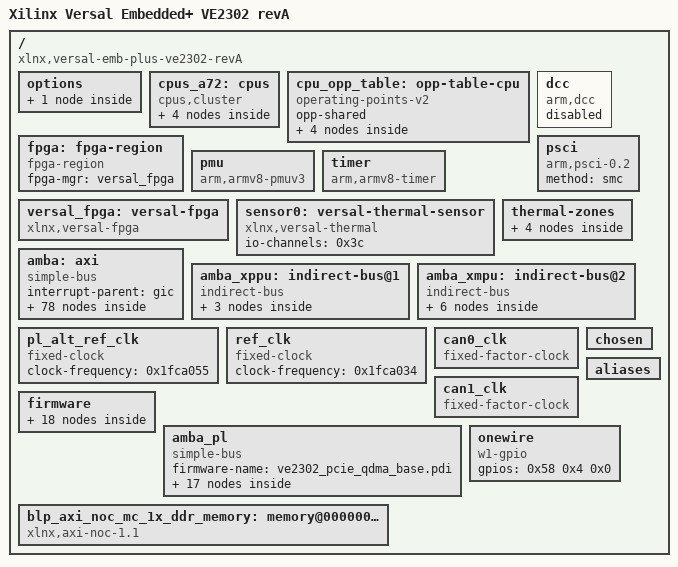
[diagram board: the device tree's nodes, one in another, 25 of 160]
/dts-v1/;

/ {
        compatible = "xlnx,versal-emb-plus-ve2302-revA", "xlnx,versal-emb-plus-ve2302", "xlnx,versal";
        #address-cells = <0x2>;
        #size-cells = <0x2>;
        model = "Xilinx Versal Embedded+ VE2302 revA";
        board = "emb-plus-vpr-4616";
        device_id = "xcve2302";
        slrcount = <0x1>;
        family = "Versal";

        options {

                u-boot {
                        compatible = "u-boot,config";
                        bootscr-address = <0x0 0x20000000>;
                };
        };

        cpus_a72: cpus {
                #address-cells = <0x1>;
                #size-cells = <0x0>;
                compatible = "cpus,cluster";
                #ranges-address-cells = <0x2>;
                #ranges-size-cells = <0x2>;
                phandle = <0xaf>;

                psv_cortexa72_0: cpu@0 {
                        compatible = "arm,cortex-a72", "arm,armv8";
                        device_type = "cpu";
                        enable-method = "psci";
                        operating-points-v2 = <&cpu_opp_table>;
                        reg = <0x0>;
                        cpu-idle-states = <&CPU_SLEEP_0>;
                        power-domains = <&versal_firmware 0x18110003>;
                        clocks = <&versal_clk 0x4d>;
                        xlnx,timestamp-clk-freq = <0x5f5e0a4>;
                        xlnx,pss-ref-clk-freq = <0x1fca034>;
                        stamp-frequency = <0x5f5e0a4>;
                        xlnx,ip-name = "psv_cortexa72";
                        xlnx,cpu-clk-freq-hz = <0x537248c1>;
                        cpu-frequency = <0x537248c1>;
                        bus-handle = <0x1>;
                        phandle = <0xb0>;
                };

                psv_cortexa72_1: cpu@1 {
                        compatible = "arm,cortex-a72", "arm,armv8";
                        device_type = "cpu";
                        enable-method = "psci";
                        operating-points-v2 = <&cpu_opp_table>;
                        reg = <0x1>;
                        cpu-idle-states = <&CPU_SLEEP_0>;
                        power-domains = <&versal_firmware 0x18110004>;
                        xlnx,timestamp-clk-freq = <0x5f5e0a4>;
                        xlnx,pss-ref-clk-freq = <0x1fca034>;
                        stamp-frequency = <0x5f5e0a4>;
                        xlnx,ip-name = "psv_cortexa72";
                        xlnx,cpu-clk-freq-hz = <0x537248c1>;
                        cpu-frequency = <0x537248c1>;
                        bus-handle = <0x1>;
                        phandle = <0xb1>;
                };

                idle-states {
                        entry-method = "psci";

                        CPU_SLEEP_0: cpu-sleep-0 {
                                compatible = "arm,idle-state";
                                arm,psci-suspend-param = <0x40000000>;
                                local-timer-stop;
                                entry-latency-us = <0x12c>;
                                exit-latency-us = <0x258>;
                                min-residency-us = <0x2710>;
                                phandle = <0x84>;
                        };
                };
        };

        cpu_opp_table: opp-table-cpu {
                compatible = "operating-points-v2";
                opp-shared;
                phandle = <0x83>;

                opp00 {
                        opp-hz = <0x0 0x47868bf4>;
                        opp-microvolt = <0xf4240>;
                        clock-latency-ns = <0x7a120>;
                };

                opp01 {
                        opp-hz = <0x0 0x23c345fa>;
                        opp-microvolt = <0xf4240>;
                        clock-latency-ns = <0x7a120>;
                };

                opp02 {
                        opp-hz = <0x0 0x17d783fc>;
                        opp-microvolt = <0xf4240>;
                        clock-latency-ns = <0x7a120>;
                };

                opp03 {
                        opp-hz = <0x0 0x11e1a2fd>;
                        opp-microvolt = <0xf4240>;
                        clock-latency-ns = <0x7a120>;
                };
        };

        dcc: dcc {
                compatible = "arm,dcc";
                status = "disabled";
                bootph-all;
                phandle = <0xba>;
        };

        fpga: fpga-region {
                compatible = "fpga-region";
                fpga-mgr = <&versal_fpga>;
                #address-cells = <0x2>;
                #size-cells = <0x2>;
                phandle = <0xbb>;
        };

        psci: psci {
                compatible = "arm,psci-0.2";
                method = "smc";
                phandle = <0xbc>;
        };

        pmu {
                compatible = "arm,armv8-pmuv3";
                interrupt-parent = <&gic>;
                interrupts = <0x1 0x7 0x304>;
        };

        timer: timer {
                compatible = "arm,armv8-timer";
                interrupt-parent = <&gic>;
                interrupts = <0x1 0xd 0x4 0x1 0xe 0x4 0x1 0xb 0x4 0x1 0xa 0x4>;
                phandle = <0xbd>;
        };

        versal_fpga: versal-fpga {
                compatible = "xlnx,versal-fpga";
                phandle = <0xa3>;
        };

        sensor0: versal-thermal-sensor {
                compatible = "xlnx,versal-thermal";
                #thermal-sensor-cells = <0x0>;
                io-channels = <0x3c>;
                io-channel-names = "sysmon-temp-channel";
                phandle = <0xa5>;
        };

        thermal-zones {

                versal_thermal: versal-thermal {
                        polling-delay-passive = <0xfa>;
                        polling-delay = <0x3e8>;
                        thermal-sensors = <0xa5>;
                        phandle = <0xbe>;

                        trips {

                                temp_alert: temp-alert {
                                        temperature = <0x11170>;
                                        hysteresis = <0x0>;
                                        type = "passive";
                                        phandle = <0xbf>;
                                };

                                ot_crit: ot-crit {
                                        temperature = <0x1e848>;
                                        hysteresis = <0x0>;
                                        type = "critical";
                                        phandle = <0xc0>;
                                };
                        };
                };
        };

        amba: axi {
                compatible = "simple-bus";
                #address-cells = <0x2>;
                #size-cells = <0x2>;
                ranges;
                interrupt-parent = <&gic>;
                bootph-all;
                phandle = <0x1>;

                can0: can@ff060000 {
                        compatible = "xlnx,canfd-2.0";
                        status = "disabled";
                        reg = <0x0 0xff060000 0x0 0x6000>;
                        interrupts = <0x0 0x14 0x4>;
                        interrupt-parent = <&gic>;
                        clock-names = "can_clk", "s_axi_aclk";
                        rx-fifo-depth = <0x40>;
                        tx-mailbox-count = <0x20>;
                        clocks = <&can0_clk>,
                         <&versal_clk 0x52>;
                        power-domains = <&versal_firmware 0x1822401f>;
                        phandle = <0xc1>;
                };

                can1: can@ff070000 {
                        compatible = "xlnx,canfd-2.0";
                        status = "disabled";
                        reg = <0x0 0xff070000 0x0 0x6000>;
                        interrupts = <0x0 0x15 0x4>;
                        interrupt-parent = <&gic>;
                        clock-names = "can_clk", "s_axi_aclk";
                        rx-fifo-depth = <0x40>;
                        tx-mailbox-count = <0x20>;
                        clocks = <&can1_clk>,
                         <&versal_clk 0x52>;
                        power-domains = <&versal_firmware 0x18224020>;
                        phandle = <0xc2>;
                };

                cci: cci@fd000000 {
                        compatible = "arm,cci-500";
                        status = "okay";
                        reg = <0x0 0xfd000000 0x0 0x10000>;
                        ranges = <0x0 0x0 0xfd000000 0xa0000>;
                        #address-cells = <0x1>;
                        #size-cells = <0x1>;
                        xlnx,ip-name = "psv_fpd_maincci";
                        phandle = <0x47>;

                        cci_pmu: pmu@10000 {
                                compatible = "arm,cci-500-pmu,r0";
                                reg = <0x10000 0x90000>;
                                interrupt-parent = <&gic>;
                                interrupts = <0x0 0x6a 0x4 0x0 0x6a 0x4 0x0 0x6a 0x4 0x0 0x6a 0x4 0x0 0x6a 0x4 0x0 0x6a 0x4 0x0 0x6a 0x4 0x0 0x6a 0x4>;
                                phandle = <0xc3>;
                        };
                };

                lpd_dma_chan0: dma-controller@ffa80000 {
                        compatible = "xlnx,zynqmp-dma-1.0";
                        status = "okay";
                        reg = <0x0 0xffa80000 0x0 0x1000>;
                        interrupts = <0x0 0x3c 0x4>;
                        interrupt-parent = <&gic>;
                        clock-names = "clk_main", "clk_apb";
                        xlnx,dma-type = <0x1>;
                        #dma-cells = <0x1>;
                        xlnx,bus-width = <0x40>;
                        clocks = <&versal_clk 0x51>,
                         <&versal_clk 0x52>;
                        power-domains = <&versal_firmware 0x18224035>;
                        xlnx,is-cache-coherent = <0x0>;
                        xlnx,ip-name = "psv_adma";
                        xlnx,dma-mode = <0x1>;
                        phandle = <0x72>;
                };

                lpd_dma_chan1: dma-controller@ffa90000 {
                        compatible = "xlnx,zynqmp-dma-1.0";
                        status = "okay";
                        reg = <0x0 0xffa90000 0x0 0x1000>;
                        interrupts = <0x0 0x3d 0x4>;
                        interrupt-parent = <&gic>;
                        clock-names = "clk_main", "clk_apb";
                        xlnx,dma-type = <0x1>;
                        #dma-cells = <0x1>;
                        xlnx,bus-width = <0x40>;
                        clocks = <&versal_clk 0x51>,
                         <&versal_clk 0x52>;
                        power-domains = <&versal_firmware 0x18224036>;
                        xlnx,is-cache-coherent = <0x0>;
                        xlnx,ip-name = "psv_adma";
                        xlnx,dma-mode = <0x1>;
                        phandle = <0x73>;
                };

                lpd_dma_chan2: dma-controller@ffaa0000 {
                        compatible = "xlnx,zynqmp-dma-1.0";
                        status = "okay";
                        reg = <0x0 0xffaa0000 0x0 0x1000>;
                        interrupts = <0x0 0x3e 0x4>;
                        interrupt-parent = <&gic>;
                        clock-names = "clk_main", "clk_apb";
                        xlnx,dma-type = <0x1>;
                        #dma-cells = <0x1>;
                        xlnx,bus-width = <0x40>;
                        clocks = <&versal_clk 0x51>,
                         <&versal_clk 0x52>;
                        power-domains = <&versal_firmware 0x18224037>;
                        xlnx,is-cache-coherent = <0x0>;
                        xlnx,ip-name = "psv_adma";
                        xlnx,dma-mode = <0x1>;
                        phandle = <0x74>;
                };

                lpd_dma_chan3: dma-controller@ffab0000 {
                        compatible = "xlnx,zynqmp-dma-1.0";
                        status = "okay";
                        reg = <0x0 0xffab0000 0x0 0x1000>;
                        interrupts = <0x0 0x3f 0x4>;
                        interrupt-parent = <&gic>;
                        clock-names = "clk_main", "clk_apb";
                        xlnx,dma-type = <0x1>;
                        #dma-cells = <0x1>;
                        xlnx,bus-width = <0x40>;
                        clocks = <&versal_clk 0x51>,
                         <&versal_clk 0x52>;
                        power-domains = <&versal_firmware 0x18224038>;
                        xlnx,is-cache-coherent = <0x0>;
                        xlnx,ip-name = "psv_adma";
                        xlnx,dma-mode = <0x1>;
                        phandle = <0x75>;
                };

                lpd_dma_chan4: dma-controller@ffac0000 {
                        compatible = "xlnx,zynqmp-dma-1.0";
                        status = "okay";
                        reg = <0x0 0xffac0000 0x0 0x1000>;
                        interrupts = <0x0 0x40 0x4>;
                        interrupt-parent = <&gic>;
                        clock-names = "clk_main", "clk_apb";
                        xlnx,dma-type = <0x1>;
                        #dma-cells = <0x1>;
                        xlnx,bus-width = <0x40>;
                        clocks = <&versal_clk 0x51>,
                         <&versal_clk 0x52>;
                        power-domains = <&versal_firmware 0x18224039>;
                        xlnx,is-cache-coherent = <0x0>;
                        xlnx,ip-name = "psv_adma";
                        xlnx,dma-mode = <0x1>;
                        phandle = <0x76>;
                };

                lpd_dma_chan5: dma-controller@ffad0000 {
                        compatible = "xlnx,zynqmp-dma-1.0";
                        status = "okay";
                        reg = <0x0 0xffad0000 0x0 0x1000>;
                        interrupts = <0x0 0x41 0x4>;
                        interrupt-parent = <&gic>;
                        clock-names = "clk_main", "clk_apb";
                        xlnx,dma-type = <0x1>;
                        #dma-cells = <0x1>;
                        xlnx,bus-width = <0x40>;
                        clocks = <&versal_clk 0x51>,
                         <&versal_clk 0x52>;
                        power-domains = <&versal_firmware 0x1822403a>;
                        xlnx,is-cache-coherent = <0x0>;
                        xlnx,ip-name = "psv_adma";
                        xlnx,dma-mode = <0x1>;
                        phandle = <0x77>;
                };

                lpd_dma_chan6: dma-controller@ffae0000 {
                        compatible = "xlnx,zynqmp-dma-1.0";
                        status = "okay";
                        reg = <0x0 0xffae0000 0x0 0x1000>;
                        interrupts = <0x0 0x42 0x4>;
                        interrupt-parent = <&gic>;
                        clock-names = "clk_main", "clk_apb";
                        xlnx,dma-type = <0x1>;
                        #dma-cells = <0x1>;
                        xlnx,bus-width = <0x40>;
                        clocks = <&versal_clk 0x51>,
                         <&versal_clk 0x52>;
                        power-domains = <&versal_firmware 0x1822403b>;
                        xlnx,is-cache-coherent = <0x0>;
                        xlnx,ip-name = "psv_adma";
                        xlnx,dma-mode = <0x1>;
                        phandle = <0x78>;
                };

                lpd_dma_chan7: dma-controller@ffaf0000 {
                        compatible = "xlnx,zynqmp-dma-1.0";
                        status = "okay";
                        reg = <0x0 0xffaf0000 0x0 0x1000>;
                        interrupts = <0x0 0x43 0x4>;
                        interrupt-parent = <&gic>;
                        clock-names = "clk_main", "clk_apb";
                        xlnx,dma-type = <0x1>;
                        #dma-cells = <0x1>;
                        xlnx,bus-width = <0x40>;
                        clocks = <&versal_clk 0x51>,
                         <&versal_clk 0x52>;
                        power-domains = <&versal_firmware 0x1822403c>;
                        xlnx,is-cache-coherent = <0x0>;
                        xlnx,ip-name = "psv_adma";
                        xlnx,dma-mode = <0x1>;
                        phandle = <0x79>;
                };

                gem0: ethernet@ff0c0000 {
                        compatible = "xlnx,versal-gem", "cdns,gem";
                        status = "disabled";
                        reg = <0x0 0xff0c0000 0x0 0x1000>;
                        interrupts = <0x0 0x38 0x4 0x0 0x38 0x4>;
                        interrupt-parent = <&gic>;
                        clock-names = "pclk", "hclk", "tx_clk", "rx_clk", "tsu_clk";
                        #address-cells = <0x1>;
                        #size-cells = <0x0>;
                        clocks = <&versal_clk 0x52>,
                         <&versal_clk 0x58>,
                         <&versal_clk 0x31>,
                         <&versal_clk 0x30>,
                         <&versal_clk 0x2b>;
                        power-domains = <&versal_firmware 0x18224019>;
                        phandle = <0xc4>;
                };

                gem1: ethernet@ff0d0000 {
                        compatible = "xlnx,versal-gem", "cdns,gem";
                        status = "disabled";
                        reg = <0x0 0xff0d0000 0x0 0x1000>;
                        interrupts = <0x0 0x3a 0x4 0x0 0x3a 0x4>;
                        interrupt-parent = <&gic>;
                        clock-names = "pclk", "hclk", "tx_clk", "rx_clk", "tsu_clk";
                        #address-cells = <0x1>;
                        #size-cells = <0x0>;
                        clocks = <&versal_clk 0x52>,
                         <&versal_clk 0x59>,
                         <&versal_clk 0x33>,
                         <&versal_clk 0x32>,
                         <&versal_clk 0x2b>;
                        power-domains = <&versal_firmware 0x1822401a>;
                        phandle = <0xc5>;
                };

                gpio0: gpio@ff0b0000 {
                        compatible = "xlnx,versal-gpio-1.0";
                        status = "okay";
                        reg = <0x0 0xff0b0000 0x0 0x1000>;
                        interrupts = <0x0 0xd 0x4>;
                        interrupt-parent = <&gic>;
                        #gpio-cells = <0x2>;
                        gpio-controller;
                        #interrupt-cells = <0x2>;
                        interrupt-controller;
                        clocks = <&versal_clk 0x52>;
                        power-domains = <&versal_firmware 0x18224023>;
                        xlnx,ip-name = "psv_gpio";
                        emio-gpio-width = [00];
                        gpio-line-names = [47 50 49 4F 5F 4C 45 44 32 00 47 50 49 4F 5F 4C 45 44 33 00 47 50 49 4F 5F 4C 45 44 34 00 00 31 57 49 52 45 00 00 46 55 53 41 00 00 45 47 50 49 4F 00 41 47 50 49 4F 00 49 32 43 30 5F 53 43 4C 00 49 32 43 30 5F 53 44 41 00 00 00 00 00 00 00 00 00 00 00 00 00 33 56 33 5F 4D 4F 4E 5F 4E 00 33 56 33 5F 4D 4F 4E 5F 50 00 00 00 00 00 00 00 00 00 00 00 00 00 00 00 00 00 00 00 00 00 00 00 00 00 00 00 00 00 00 00 00];
                        phandle = <0x58>;
                };

                gpio1: gpio@f1020000 {
                        compatible = "xlnx,pmc-gpio-1.0";
                        status = "okay";
                        reg = <0x0 0xf1020000 0x0 0x1000>;
                        interrupts = <0x0 0x7a 0x4>;
                        interrupt-parent = <&gic>;
                        #gpio-cells = <0x2>;
                        gpio-controller;
                        #interrupt-cells = <0x2>;
                        interrupt-controller;
                        clocks = <&versal_clk 0x3d>;
                        power-domains = <&versal_firmware 0x1822402c>;
                        xlnx,ip-name = "psv_pmc_gpio";
                        phandle = <0x2f>;
                };

                i2c0: i2c@ff020000 {
                        compatible = "cdns,i2c-r1p14";
                        status = "disabled";
                        reg = <0x0 0xff020000 0x0 0x1000>;
                        interrupts = <0x0 0xe 0x4>;
                        interrupt-parent = <&gic>;
                        clock-frequency = <0x186a0>;
                        #address-cells = <0x1>;
                        #size-cells = <0x0>;
                        clocks = <&versal_clk 0x62>;
                        power-domains = <&versal_firmware 0x1822401d>;
                        phandle = <0xc6>;
                };

                i2c1: i2c@ff030000 {
                        compatible = "cdns,i2c-r1p14";
                        status = "disabled";
                        reg = <0x0 0xff030000 0x0 0x1000>;
                        interrupts = <0x0 0xf 0x4>;
                        interrupt-parent = <&gic>;
                        clock-frequency = <0x186a0>;
                        #address-cells = <0x1>;
                        #size-cells = <0x0>;
                        clocks = <&versal_clk 0x63>;
                        power-domains = <&versal_firmware 0x1822401e>;
                        phandle = <0xc7>;
                };

                i2c2: i2c@f1000000 {
                        compatible = "cdns,i2c-r1p14";
                        status = "okay";
                        reg = <0x0 0xf1000000 0x0 0x1000>;
                        interrupts = <0x0 0x7b 0x4>;
                        interrupt-parent = <&gic>;
                        clock-frequency = <0x186a0>;
                        #address-cells = <0x1>;
                        #size-cells = <0x0>;
                        clocks = <&versal_clk 0x3e>;
                        power-domains = <&versal_firmware 0x1822402d>;
                        xlnx,clock-freq = <0x5f5e0a4>;
                        xlnx,i2c-clk-freq-hz = <0x5f5e0a4>;
                        xlnx,ip-name = "psv_pmc_i2c";
                        phandle = <0x2d>;
                };

                mc1: memory-controller@f62c0000 {
                        compatible = "xlnx,versal-ddrmc";
                        status = "disabled";
                        reg = <0x0 0xf62c0000 0x0 0x2000 0x0 0xf6210000 0x0 0x20000>;
                        reg-names = "base", "noc";
                        interrupts = <0x0 0x93 0x4>;
                        interrupt-parent = <&gic>;
                        phandle = <0xc9>;
                };

                mc2: memory-controller@f6430000 {
                        compatible = "xlnx,versal-ddrmc";
                        status = "disabled";
                        reg = <0x0 0xf6430000 0x0 0x2000 0x0 0xf6380000 0x0 0x20000>;
                        reg-names = "base", "noc";
                        interrupts = <0x0 0x93 0x4>;
                        interrupt-parent = <&gic>;
                        phandle = <0xca>;
                };

                mc3: memory-controller@f65a0000 {
                        compatible = "xlnx,versal-ddrmc";
                        status = "disabled";
                        reg = <0x0 0xf65a0000 0x0 0x2000 0x0 0xf64f0000 0x0 0x20000>;
                        reg-names = "base", "noc";
                        interrupts = <0x0 0x93 0x4>;
                        interrupt-parent = <&gic>;
                        phandle = <0xcb>;
                };

                ocm: memory-controller@ff960000 {
                        compatible = "xlnx,zynqmp-ocmc-1.0";
                        reg = <0x0 0xff960000 0x0 0x1000>;
                        interrupts = <0x0 0xa 0x4>;
                        interrupt-parent = <&gic>;
                        phandle = <0xcc>;
                };

                rtc: rtc@f12a0000 {
                        compatible = "xlnx,zynqmp-rtc";
                        status = "okay";
                        reg = <0x0 0xf12a0000 0x0 0x100>;
                        interrupt-names = "alarm", "sec";
                        interrupts = <0x0 0x8e 0x4 0x0 0x8f 0x4>;
                        interrupt-parent = <&gic>;
                        calibration = <0x7fff>;
                        power-domains = <&versal_firmware 0x18224034>;
                        xlnx,ip-name = "psv_pmc_rtc";
                        phandle = <0x3d>;
                };

                sdhci0: mmc@f1040000 {
                        compatible = "xlnx,versal-8.9a", "arasan,sdhci-8.9a";
                        status = "disabled";
                        reg = <0x0 0xf1040000 0x0 0x10000>;
                        interrupts = <0x0 0x7e 0x4>;
                        interrupt-parent = <&gic>;
                        clock-names = "clk_xin", "clk_ahb", "gate";
                        #clock-cells = <0x1>;
                        clock-output-names = "clk_out_sd0", "clk_in_sd0";
                        clocks = <&versal_clk 0x3b>,
                         <&versal_clk 0x52>,
                         <&versal_clk 0x4a>;
                        power-domains = <&versal_firmware 0x1822402e>;
                        phandle = <0xcd>;
                };

                sdhci1: mmc@f1050000 {
                        compatible = "xlnx,versal-8.9a", "arasan,sdhci-8.9a";
                        status = "disabled";
                        reg = <0x0 0xf1050000 0x0 0x10000>;
                        interrupts = <0x0 0x80 0x4>;
                        interrupt-parent = <&gic>;
                        clock-names = "clk_xin", "clk_ahb", "gate";
                        #clock-cells = <0x1>;
                        clock-output-names = "clk_out_sd1", "clk_in_sd1";
                        clocks = <&versal_clk 0x3c>,
                         <&versal_clk 0x52>,
                         <&versal_clk 0x4a>;
                        power-domains = <&versal_firmware 0x1822402f>;
                        phandle = <0xce>;
                };

                serial0: serial@ff000000 {
                        compatible = "arm,pl011", "arm,primecell";
                        status = "okay";
                        reg = <0x0 0xff000000 0x0 0x1000>;
                        interrupts = <0x0 0x12 0x4>;
                        interrupt-parent = <&gic>;
                        reg-io-width = <0x4>;
                        clock-names = "uartclk", "apb_pclk";
                        bootph-all;
                        clocks = <&versal_clk 0x5c>,
                         <&versal_clk 0x52>;
                        power-domains = <&versal_firmware 0x18224021>;
                        xlnx,has-modem = <0x0>;
                        xlnx,uart-clk-freq-hz = <0x5f5e0a4>;
                        port-number = <0x0>;
                        xlnx,ip-name = "psv_sbsauart";
                        xlnx,uart-board-interface = "custom";
                        xlnx,baudrate = <0x1c200>;
                        cts-override;
                        u-boot,dm-pre-reloc;
                        xlnx,clock-freq = <0x5f5e0a4>;
                        phandle = <0x53>;
                };

                serial1: serial@ff010000 {
                        compatible = "arm,pl011", "arm,primecell";
                        status = "okay";
                        reg = <0x0 0xff010000 0x0 0x1000>;
                        interrupts = <0x0 0x13 0x4>;
                        interrupt-parent = <&gic>;
                        reg-io-width = <0x4>;
                        clock-names = "uartclk", "apb_pclk";
                        bootph-all;
                        clocks = <&versal_clk 0x5d>,
                         <&versal_clk 0x52>;
                        power-domains = <&versal_firmware 0x18224022>;
                        xlnx,has-modem = <0x0>;
                        xlnx,uart-clk-freq-hz = <0x5f5e0a4>;
                        port-number = <0x0>;
                        xlnx,ip-name = "psv_sbsauart";
                        xlnx,uart-board-interface = "custom";
                        xlnx,baudrate = <0x1c200>;
                        cts-override;
                        u-boot,dm-pre-reloc;
                        xlnx,clock-freq = <0x5f5e0a4>;
                        phandle = <0x54>;
                };

                smmu: iommu@fd800000 {
                        compatible = "arm,mmu-500";
                        status = "okay";
                        reg = <0x0 0xfd800000 0x0 0x40000>;
                        stream-match-mask = <0x7c00>;
                        #iommu-cells = <0x1>;
                        #global-interrupts = <0x1>;
                        interrupts = <0x0 0x6b 0x4 0x0 0x6b 0x4 0x0 0x6b 0x4 0x0 0x6b 0x4 0x0 0x6b 0x4 0x0 0x6b 0x4 0x0 0x6b 0x4 0x0 0x6b 0x4 0x0 0x6b 0x4 0x0 0x6b 0x4 0x0 0x6b 0x4 0x0 0x6b 0x4 0x0 0x6b 0x4 0x0 0x6b 0x4 0x0 0x6b 0x4 0x0 0x6b 0x4 0x0 0x6b 0x4 0x0 0x6b 0x4 0x0 0x6b 0x4 0x0 0x6b 0x4 0x0 0x6b 0x4 0x0 0x6b 0x4 0x0 0x6b 0x4 0x0 0x6b 0x4 0x0 0x6b 0x4 0x0 0x6b 0x4 0x0 0x6b 0x4 0x0 0x6b 0x4 0x0 0x6b 0x4 0x0 0x6b 0x4 0x0 0x6b 0x4 0x0 0x6b 0x4 0x0 0x6b 0x4>;
                        interrupt-parent = <&gic>;
                        xlnx,ip-name = "psv_fpd_smmutcu";
                        phandle = <0x52>;
                };

                ospi: spi@f1010000 {
                        compatible = "xlnx,versal-ospi-1.0", "cdns,qspi-nor";
                        status = "okay";
                        reg = <0x0 0xf1010000 0x0 0x10000 0x0 0xc0000000 0x0 0x20000000>;
                        interrupts = <0x0 0x7c 0x4>;
                        interrupt-parent = <&gic>;
                        cdns,fifo-depth = <0x100>;
                        cdns,fifo-width = <0x4>;
                        cdns,is-dma = <0x1>;
                        cdns,trigger-address = <0xc0000000>;
                        #address-cells = <0x1>;
                        #size-cells = <0x0>;
                        clocks = <&versal_clk 0x3a>;
                        power-domains = <&versal_firmware 0x1822402a>;
                        reset-names = "qspi";
                        resets = <&versal_reset 0xc10402e>;
                        is-stacked = <0x0>;
                        xlnx,is-cache-coherent = <0x0>;
                        xlnx,clock-freq = <0xbebc149>;
                        xlnx,ip-name = "psv_pmc_ospi";
                        xlnx,ospi-clk-freq-hz = <0xbebc149>;
                        is-dual = <0x0>;
                        xlnx,ospi-mode = <0x0>;
                        phandle = <0x2e>;
                };

                qspi: spi@f1030000 {
                        compatible = "xlnx,versal-qspi-1.0";
                        status = "disabled";
                        reg = <0x0 0xf1030000 0x0 0x1000>;
                        interrupts = <0x0 0x7d 0x4>;
                        interrupt-parent = <&gic>;
                        clock-names = "ref_clk", "pclk";
                        #address-cells = <0x1>;
                        #size-cells = <0x0>;
                        clocks = <&versal_clk 0x39>,
                         <&versal_clk 0x52>;
                        power-domains = <&versal_firmware 0x1822402b>;
                        phandle = <0xcf>;
                };

                spi0: spi@ff040000 {
                        compatible = "cdns,spi-r1p6";
                        status = "okay";
                        reg = <0x0 0xff040000 0x0 0x1000>;
                        interrupts = <0x0 0x10 0x4>;
                        interrupt-parent = <&gic>;
                        clock-names = "ref_clk", "pclk";
                        #address-cells = <0x1>;
                        #size-cells = <0x0>;
                        clocks = <&versal_clk 0x5e>,
                         <&versal_clk 0x52>;
                        power-domains = <&versal_firmware 0x1822401b>;
                        xlnx,spi-board-interface = "custom";
                        xlnx,has-ss0 = <0x1>;
                        xlnx,ip-name = "psv_spi";
                        xlnx,has-ss1 = <0x0>;
                        num-cs = <0x1>;
                        xlnx,spi-clk-freq-hz = <0xbebc149>;
                        xlnx,has-ss2 = <0x0>;
                        phandle = <0x55>;
                };

                spi1: spi@ff050000 {
                        compatible = "cdns,spi-r1p6";
                        status = "disabled";
                        reg = <0x0 0xff050000 0x0 0x1000>;
                        interrupts = <0x0 0x11 0x4>;
                        interrupt-parent = <&gic>;
                        clock-names = "ref_clk", "pclk";
                        #address-cells = <0x1>;
                        #size-cells = <0x0>;
                        clocks = <&versal_clk 0x5f>,
                         <&versal_clk 0x52>;
                        power-domains = <&versal_firmware 0x1822401c>;
                        phandle = <0xd0>;
                };

                sysmon0: sysmon@f1270000 {
                        compatible = "xlnx,versal-sysmon";
                        #io-channel-cells = <0x0>;
                        reg = <0x0 0xf1270000 0x0 0x4000>;
                        interrupts = <0x0 0x90 0x4>;
                        xlnx,numchannels = [0B];
                        #address-cells = <0x2>;
                        #size-cells = <0x2>;
                        xlnx,nodeid = <0x18224055>;
                        xlnx,sat-63-desc = "PS , FPD , satellite";
                        xlnx,sat-1-desc = "PMC , system , ADC";
                        xlnx,sat-9-x = <0xae2>;
                        xlnx,sat-9-y = <0x2905>;
                        xlnx,meas-0-root-id = <0x1>;
                        xlnx,meas-7-slr-number = <0x0>;
                        xlnx,meas-10-root-id = <0x0>;
                        xlnx,ip-name = "psv_pmc_sysmon";
                        xlnx,meas-1-root-id = <0x5>;
                        xlnx,meas-2-root-id = <0x8>;
                        xlnx,meas-2-slr-number = <0x0>;
                        xlnx,meas-3-root-id = <0xa>;
                        xlnx,sat-9-desc = "ME , satellite";
                        xlnx,meas-4-root-id = <0x7>;
                        xlnx,meas-5-root-id = <0x2>;
                        xlnx,sat-10-x = <0x319>;
                        xlnx,sat-64-x = <0x23>;
                        xlnx,sat-2-x = <0x23>;
                        xlnx,meas-6-root-id = <0x3>;
                        xlnx,sat-10-y = <0x2905>;
                        xlnx,sat-64-y = <0xb34>;
                        xlnx,sat-2-y = <0xb34>;
                        xlnx,sat-13-desc = "Clocking , column , satellite";
                        xlnx,meas-7-root-id = <0x4>;
                        xlnx,meas-8-root-id = <0x6>;
                        xlnx,sat-6-desc = "VNOC , satellite";
                        xlnx,meas-9-root-id = <0x9>;
                        xlnx,sat-6-x = <0x1a37>;
                        xlnx,sat-6-y = <0x19f9>;
                        xlnx,sat-10-desc = "ME , satellite";
                        xlnx,sat-3-desc = "XPIO , satellite";
                        xlnx,meas-5-slr-number = <0x0>;
                        xlnx,meas-10-aux-io-n = "LPD_MIO25_502";
                        xlnx,meas-0-slr-number = <0x0>;
                        xlnx,meas-10-aux-io-p = "LPD_MIO24_502";
                        xlnx,sat-11-x = <0xa0e>;
                        xlnx,sat-3-x = <0x116a>;
                        xlnx,sat-11-y = <0x23fc>;
                        xlnx,sat-3-y = <0x5ff>;
                        status = "okay";
                        xlnx,meas-8-slr-number = <0x0>;
                        xlnx,sat-8-desc = "ME , satellite";
                        xlnx,sat-7-x = <0x1a74>;
                        xlnx,sat-7-y = <0x2905>;
                        xlnx,meas-3-slr-number = <0x0>;
                        xlnx,sat-12-desc = "Clocking , column , satellite";
                        xlnx,sat-5-desc = "VNOC , satellite";
                        xlnx,sat-64-desc = "PS , LPD , satellite";
                        xlnx,sat-2-desc = "PMC , user , ADC";
                        xlnx,meas-6-slr-number = <0x0>;
                        xlnx,sat-12-x = <0xa0e>;
                        xlnx,sat-4-x = <0x1d4c>;
                        xlnx,sat-12-y = <0x1dc4>;
                        xlnx,sat-4-y = <0x5ff>;
                        xlnx,meas-10-slr-number = <0x0>;
                        xlnx,meas-1-slr-number = <0x0>;
                        xlnx,sat-8-x = <0x12ab>;
                        xlnx,sat-8-y = <0x2905>;
                        xlnx,meas-0 = "VCCAUX";
                        xlnx,meas-10 = "VAUX_CH0";
                        xlnx,meas-1 = "VCC_SOC";
                        xlnx,meas-2 = "VCCO_302";
                        xlnx,meas-3 = "VCCAUX_PMC";
                        xlnx,meas-4 = "VCCO_500";
                        xlnx,sat-7-desc = "ME , satellite";
                        xlnx,meas-5 = "VCC_PMC";
                        xlnx,meas-9-slr-number = <0x0>;
                        xlnx,meas-6 = "VCC_PSFP";
                        xlnx,meas-7 = "VCC_PSLP";
                        xlnx,sat-63-x = <0x23>;
                        xlnx,sat-1-x = <0x23>;
                        xlnx,meas-4-slr-number = <0x0>;
                        xlnx,meas-8 = "VP_VN";
                        xlnx,sat-11-desc = "Clocking , column , satellite";
                        xlnx,sat-63-y = <0xb34>;
                        xlnx,sat-1-y = <0xb34>;
                        xlnx,meas-9 = "VCCO_703";
                        xlnx,sat-4-desc = "XPIO , satellite";
                        xlnx,sat-13-x = <0xa0e>;
                        xlnx,sat-5-x = <0x1a37>;
                        xlnx,sat-13-y = <0x1795>;
                        xlnx,sat-5-y = <0xe06>;
                        phandle = <0x3c>;

                        supply@1 {
                                reg = <0x1>;
                                xlnx,name = "vccaux";
                        };

                        supply@5 {
                                reg = <0x5>;
                                xlnx,name = "vcc_soc";
                        };

                        supply@8 {
                                reg = <0x8>;
                                xlnx,name = "vcco_302";
                        };

                        supply@10 {
                                reg = <0xa>;
                                xlnx,name = "vccaux_pmc";
                        };

                        supply@7 {
                                reg = <0x7>;
                                xlnx,name = "vcco_500";
                        };

                        supply@2 {
                                reg = <0x2>;
                                xlnx,name = "vcc_pmc";
                        };

                        supply@3 {
                                reg = <0x3>;
                                xlnx,name = "vcc_psfp";
                        };

                        supply@4 {
                                reg = <0x4>;
                                xlnx,name = "vcc_pslp";
                        };

                        supply@6 {
                                reg = <0x6>;
                                xlnx,name = "vp_vn";
                        };

                        supply@9 {
                                reg = <0x9>;
                                xlnx,name = "vcco_703";
                        };

                        supply@0 {
                                reg = <0x0>;
                                xlnx,name = "vaux_ch0";
                        };
                };

                sysmon1: sysmon@109270000 {
                        compatible = "xlnx,versal-sysmon";
                        status = "disabled";
                        reg = <0x1 0x9270000 0x0 0x4000>;
                        xlnx,numchannels = [00];
                        #address-cells = <0x1>;
                        #size-cells = <0x0>;
                        xlnx,nodeid = <0x18225055>;
                        phandle = <0xd1>;
                };

                sysmon2: sysmon@111270000 {
                        compatible = "xlnx,versal-sysmon";
                        status = "disabled";
                        reg = <0x1 0x11270000 0x0 0x4000>;
                        xlnx,numchannels = [00];
                        #address-cells = <0x1>;
                        #size-cells = <0x0>;
                        xlnx,nodeid = <0x18226055>;
                        phandle = <0xd2>;
                };

                sysmon3: sysmon@119270000 {
                        compatible = "xlnx,versal-sysmon";
                        status = "disabled";
                        reg = <0x1 0x19270000 0x0 0x4000>;
                        xlnx,numchannels = [00];
                        #address-cells = <0x1>;
                        #size-cells = <0x0>;
                        xlnx,nodeid = <0x18227055>;
                        phandle = <0xd3>;
                };

                ttc0: timer@ff0e0000 {
                        compatible = "cdns,ttc";
                        status = "okay";
                        interrupts = <0x0 0x25 0x4 0x0 0x26 0x4 0x0 0x27 0x4>;
                        interrupt-parent = <&gic>;
                        reg = <0x0 0xff0e0000 0x0 0x1000>;
                        timer-width = <0x20>;
                        clocks = <&versal_clk 0x27>,
                         <&versal_clk 0x52>;
                        power-domains = <&versal_firmware 0x18224024>;
                        xlnx,ttc-clk2-clksrc = <0x0>;
                        xlnx,ip-name = "psv_ttc";
                        xlnx,ttc-clk1-clksrc = <0x0>;
                        xlnx,ttc-clk0-freq-hz = <0x8f0d0f7>;
                        xlnx,ttc-clk1-freq-hz = <0x8f0d0f7>;
                        xlnx,ttc-clk2-freq-hz = <0x8f0d0f7>;
                        xlnx,ttc-board-interface = "custom";
                        xlnx,clock-freq = <0x8f0d0f7>;
                        xlnx,ttc-clk0-clksrc = <0x0>;
                        phandle = <0x59>;
                };

                ttc1: timer@ff0f0000 {
                        compatible = "cdns,ttc";
                        status = "okay";
                        interrupts = <0x0 0x28 0x4 0x0 0x29 0x4 0x0 0x2a 0x4>;
                        interrupt-parent = <&gic>;
                        reg = <0x0 0xff0f0000 0x0 0x1000>;
                        timer-width = <0x20>;
                        clocks = <&versal_clk 0x28>,
                         <&versal_clk 0x52>;
                        power-domains = <&versal_firmware 0x18224025>;
                        xlnx,ttc-clk2-clksrc = <0x0>;
                        xlnx,ip-name = "psv_ttc";
                        xlnx,ttc-clk1-clksrc = <0x0>;
                        xlnx,ttc-clk0-freq-hz = <0x8f0d0f7>;
                        xlnx,ttc-clk1-freq-hz = <0x8f0d0f7>;
                        xlnx,ttc-clk2-freq-hz = <0x8f0d0f7>;
                        xlnx,ttc-board-interface = "custom";
                        xlnx,clock-freq = <0x8f0d0f7>;
                        xlnx,ttc-clk0-clksrc = <0x0>;
                        phandle = <0x5a>;
                };

                ttc2: timer@ff100000 {
                        compatible = "cdns,ttc";
                        status = "okay";
                        interrupts = <0x0 0x2b 0x4 0x0 0x2c 0x4 0x0 0x2d 0x4>;
                        interrupt-parent = <&gic>;
                        reg = <0x0 0xff100000 0x0 0x1000>;
                        timer-width = <0x20>;
                        clocks = <&versal_clk 0x29>,
                         <&versal_clk 0x52>;
                        power-domains = <&versal_firmware 0x18224026>;
                        xlnx,ttc-clk2-clksrc = <0x0>;
                        xlnx,ip-name = "psv_ttc";
                        xlnx,ttc-clk1-clksrc = <0x0>;
                        xlnx,ttc-clk0-freq-hz = <0x8f0d0f7>;
                        xlnx,ttc-clk1-freq-hz = <0x8f0d0f7>;
                        xlnx,ttc-clk2-freq-hz = <0x8f0d0f7>;
                        xlnx,ttc-board-interface = "custom";
                        xlnx,clock-freq = <0x8f0d0f7>;
                        xlnx,ttc-clk0-clksrc = <0x0>;
                        phandle = <0x5b>;
                };

                ttc3: timer@ff110000 {
                        compatible = "cdns,ttc";
                        status = "okay";
                        interrupts = <0x0 0x2e 0x4 0x0 0x2f 0x4 0x0 0x30 0x4>;
                        interrupt-parent = <&gic>;
                        reg = <0x0 0xff110000 0x0 0x1000>;
                        timer-width = <0x20>;
                        clocks = <&versal_clk 0x2a>,
                         <&versal_clk 0x52>;
                        power-domains = <&versal_firmware 0x18224027>;
                        xlnx,ttc-clk2-clksrc = <0x0>;
                        xlnx,ip-name = "psv_ttc";
                        xlnx,ttc-clk1-clksrc = <0x0>;
                        xlnx,ttc-clk0-freq-hz = <0x8f0d0f7>;
                        xlnx,ttc-clk1-freq-hz = <0x8f0d0f7>;
                        xlnx,ttc-clk2-freq-hz = <0x8f0d0f7>;
                        xlnx,ttc-board-interface = "custom";
                        xlnx,clock-freq = <0x8f0d0f7>;
                        xlnx,ttc-clk0-clksrc = <0x0>;
                        phandle = <0x5c>;
                };

                usb0: usb@ff9d0000 {
                        compatible = "xlnx,versal-dwc3";
                        status = "disabled";
                        reg = <0x0 0xff9d0000 0x0 0x100>;
                        clock-names = "bus_clk", "ref_clk";
                        ranges;
                        #address-cells = <0x2>;
                        #size-cells = <0x2>;
                        clocks = <&versal_clk 0x5b>,
                         <&versal_clk 0x68>;
                        power-domains = <&versal_firmware 0x18224018>;
                        resets = <&versal_reset 0xc104036>;
                        phandle = <0xd4>;

                        dwc3_0: usb@fe200000 {
                                compatible = "snps,dwc3";
                                status = "disabled";
                                reg = <0x0 0xfe200000 0x0 0x10000>;
                                interrupt-names = "host", "peripheral", "otg", "wakeup";
                                interrupts = <0x0 0x16 0x4 0x0 0x16 0x4 0x0 0x1a 0x4 0x0 0x4a 0x4>;
                                snps,dis_u2_susphy_quirk;
                                snps,dis_u3_susphy_quirk;
                                snps,quirk-frame-length-adjustment = <0x20>;
                                clock-names = "ref";
                                clocks = <&versal_clk 0x5b>;
                                phandle = <0xd5>;
                        };
                };

                cpm_pciea: pci@fca10000 {
                        device_type = "pci";
                        #address-cells = <0x3>;
                        #interrupt-cells = <0x1>;
                        #size-cells = <0x2>;
                        compatible = "xlnx,versal-cpm-host-1.00";
                        status = "disabled";
                        interrupt-map = <0x0 0x0 0x0 0x1 &pcie_intc_0 0x0>,
                         <0x0 0x0 0x0 0x2 &pcie_intc_0 0x1>,
                         <0x0 0x0 0x0 0x3 &pcie_intc_0 0x2>,
                         <0x0 0x0 0x0 0x4 &pcie_intc_0 0x3>;
                        interrupt-map-mask = <0x0 0x0 0x0 0x7>;
                        interrupt-names = "misc";
                        interrupts = <0x0 0x48 0x4>;
                        xlnx,csr-slcr = <0x6 0x0>;
                        xlnx,num-of-bars = <0x2>;
                        xlnx,port-type = <0x1>;
                        interrupt-parent = <&gic>;
                        bus-range = <0x0 0xff>;
                        ranges = <0x2000000 0x0 0xe0010000 0x0 0xe0010000 0x0 0x10000000 0x43000000 0x80 0x0 0x80 0x0 0x0 0x80000000>;
                        msi-map = <0x0 0x4 0x0 0x10000>;
                        reg = <0x6 0x0 0x0 0x1000000 0x0 0xfca10000 0x0 0x1000>;
                        reg-names = "cfg", "cpm_slcr";
                        phandle = <0xd6>;

                        pcie_intc_0: interrupt-controller {
                                #address-cells = <0x0>;
                                #interrupt-cells = <0x1>;
                                interrupt-controller;
                                phandle = <0xa9>;
                        };
                };

                cpm5_pcie: pcie@fcdd0000 {
                        device_type = "pci";
                        #address-cells = <0x3>;
                        #interrupt-cells = <0x1>;
                        #size-cells = <0x2>;
                        compatible = "xlnx,versal-cpm5-host";
                        status = "disabled";
                        interrupt-map = <0x0 0x0 0x0 0x1 &pcie_intc_2 0x0>,
                         <0x0 0x0 0x0 0x2 &pcie_intc_2 0x1>,
                         <0x0 0x0 0x0 0x3 &pcie_intc_2 0x2>,
                         <0x0 0x0 0x0 0x4 &pcie_intc_2 0x3>;
                        interrupt-map-mask = <0x0 0x0 0x0 0x7>;
                        interrupt-names = "misc";
                        interrupts = <0x0 0x48 0x4>;
                        xlnx,csr-slcr = <0xfce20000>;
                        xlnx,num-of-bars = <0x2>;
                        xlnx,port-type = <0x1>;
                        interrupt-parent = <&gic>;
                        bus-range = <0x0 0xff>;
                        ranges = <0x2000000 0x0 0xe0000000 0x0 0xe0000000 0x0 0x10000000 0x43000000 0x80 0x0 0x80 0x0 0x0 0x80000000>;
                        msi-map = <0x0 0x4 0x0 0x10000>;
                        reg = <0x6 0x0 0x0 0x1000000 0x0 0xfcdd0000 0x0 0x1000 0x0 0xfce20000 0x0 0x1000000>;
                        reg-names = "cfg", "cpm_slcr", "cpm_csr";
                        phandle = <0xd7>;

                        pcie_intc_2: interrupt-controller {
                                #address-cells = <0x0>;
                                #interrupt-cells = <0x1>;
                                interrupt-controller;
                                phandle = <0xaa>;
                        };
                };

                watchdog: watchdog@fd4d0000 {
                        compatible = "xlnx,versal-wwdt";
                        status = "disabled";
                        reg = <0x0 0xfd4d0000 0x0 0x10000>;
                        interrupt-names = "wdt", "wwdt_reset_pending", "gwdt", "gwdt_reset_pending";
                        interrupts = <0x0 0x64 0x1 0x0 0x6d 0x1 0x0 0x6c 0x1 0x0 0x6e 0x1>;
                        interrupt-parent = <&gic>;
                        timeout-sec = <0x1e>;
                        clocks = <&versal_clk 0x4c>;
                        power-domains = <&versal_firmware 0x18224029>;
                        phandle = <0xd8>;
                };

                watchdog1: watchdog@ff120000 {
                        compatible = "xlnx,versal-wwdt";
                        status = "disabled";
                        reg = <0x0 0xff120000 0x0 0x10000>;
                        interrupt-parent = <&gic>;
                        interrupt-names = "wdt", "wwdt_reset_pending", "gwdt", "gwdt_reset_pending";
                        interrupts = <0x0 0x31 0x1 0x0 0x45 0x1 0x0 0x46 0x4 0x0 0x47 0x4>;
                        timeout-sec = <0x1e>;
                        clocks = <&versal_clk 0x52>;
                        power-domains = <&versal_firmware 0x18224028>;
                        phandle = <0xd9>;
                };

                xilsem_edac: edac@f2014050 {
                        compatible = "xlnx,versal-xilsem-edac";
                        status = "disabled";
                        reg = <0x0 0xf2014050 0x0 0xc4>;
                        phandle = <0xda>;
                };

                dma0: pmcdma@f11c0000 {
                        status = "okay";
                        compatible = "xlnx,zynqmp-csudma-1.0";
                        interrupt-parent = <&gic>;
                        interrupts = <0x0 0x83 0x4>;
                        reg = <0x0 0xf11c0000 0x0 0x10000>;
                        xlnx,dma-type = <0x1>;
                        xlnx,ip-name = "psv_pmc_dma";
                        phandle = <0x31>;
                };

                dma1: pmcdma@f11d0000 {
                        status = "okay";
                        compatible = "xlnx,zynqmp-csudma-1.0";
                        interrupt-parent = <&gic>;
                        interrupts = <0x0 0x84 0x4>;
                        reg = <0x0 0xf11d0000 0x0 0x10000>;
                        xlnx,dma-type = <0x2>;
                        xlnx,ip-name = "psv_pmc_dma";
                        phandle = <0x32>;
                };

                coresight: coresight@f0800000 {
                        compatible = "xlnx,coresight-1.0";
                        status = "okay";
                        reg = <0x0 0xf0800000 0x0 0x10000>;
                        xlnx,ip-name = "psv_coresight";
                        phandle = <0x14>;
                };

                blp_cips_pspmc_0_psv_cpm: blp_cips_pspmc_0_psv_cpm@0 {
                        compatible = "xlnx,psv-cpm-1.0";
                        status = "okay";
                        xlnx,ip-name = "psv_cpm";
                        reg = <0x0 0xfc000000 0x0 0x1000000>;
                        phandle = <0x46>;
                };

                blp_cips_pspmc_0_psv_xram_atm: blp_cips_pspmc_0_psv_xram_atm@ff970000 {
                        compatible = "xlnx,psv-xram-atm-1.0";
                        status = "okay";
                        xlnx,ip-name = "psv_xram_atm";
                        reg = <0x0 0xff970000 0x0 0x10000>;
                        phandle = <0x6d>;
                };

                blp_cips_pspmc_0_psv_xram_ctrl_1: blp_cips_pspmc_0_psv_xram_ctrl_1@ff8e0000 {
                        compatible = "xlnx,psv-xram-ctrl-1.0";
                        status = "okay";
                        xlnx,ip-name = "psv_xram_ctrl";
                        reg = <0x0 0xff8e0000 0x0 0x10000>;
                        phandle = <0x62>;
                };

                blp_cips_pspmc_0_psv_xram_ctrl_2: blp_cips_pspmc_0_psv_xram_ctrl_2@ff8f0000 {
                        compatible = "xlnx,psv-xram-ctrl-1.0";
                        status = "okay";
                        xlnx,ip-name = "psv_xram_ctrl";
                        reg = <0x0 0xff8f0000 0x0 0x10000>;
                        phandle = <0x63>;
                };

                blp_cips_pspmc_0_psv_xram_ctrl_3: blp_cips_pspmc_0_psv_xram_ctrl_3@ff900000 {
                        compatible = "xlnx,psv-xram-ctrl-1.0";
                        status = "okay";
                        xlnx,ip-name = "psv_xram_ctrl";
                        reg = <0x0 0xff900000 0x0 0x10000>;
                        phandle = <0x64>;
                };

                blp_cips_pspmc_0_psv_xram_ctrl_4: blp_cips_pspmc_0_psv_xram_ctrl_4@ff910000 {
                        compatible = "xlnx,psv-xram-ctrl-1.0";
                        status = "okay";
                        xlnx,ip-name = "psv_xram_ctrl";
                        reg = <0x0 0xff910000 0x0 0x10000>;
                        phandle = <0x65>;
                };

                blp_cips_pspmc_0_psv_xram_global_ctrl: blp_cips_pspmc_0_psv_xram_global_ctrl@ff950000 {
                        compatible = "xlnx,psv-xram-global-ctrl-1.0";
                        status = "okay";
                        xlnx,ip-name = "psv_xram_global_ctrl";
                        reg = <0x0 0xff950000 0x0 0x10000>;
                        phandle = <0x6b>;
                };

                blp_cips_pspmc_0_psv_xram_gpv: blp_cips_pspmc_0_psv_xram_gpv@ff940000 {
                        compatible = "xlnx,psv-xram-gpv-1.0";
                        status = "okay";
                        xlnx,ip-name = "psv_xram_gpv";
                        reg = <0x0 0xff940000 0x0 0x10000>;
                        phandle = <0x6a>;
                };

                blp_cips_pspmc_0_psv_xram_xmpu_bank_1: blp_cips_pspmc_0_psv_xram_xmpu_bank_1@ff930000 {
                        compatible = "xlnx,psv-xram-xmpu-bank-1.0";
                        status = "okay";
                        xlnx,ip-name = "psv_xram_xmpu_bank";
                        reg = <0x0 0xff930000 0x0 0x4000>;
                        phandle = <0x66>;
                };

                blp_cips_pspmc_0_psv_xram_xmpu_bank_2: blp_cips_pspmc_0_psv_xram_xmpu_bank_2@ff934000 {
                        compatible = "xlnx,psv-xram-xmpu-bank-1.0";
                        status = "okay";
                        xlnx,ip-name = "psv_xram_xmpu_bank";
                        reg = <0x0 0xff934000 0x0 0x4000>;
                        phandle = <0x67>;
                };

                blp_cips_pspmc_0_psv_xram_xmpu_bank_3: blp_cips_pspmc_0_psv_xram_xmpu_bank_3@ff938000 {
                        compatible = "xlnx,psv-xram-xmpu-bank-1.0";
                        status = "okay";
                        xlnx,ip-name = "psv_xram_xmpu_bank";
                        reg = <0x0 0xff938000 0x0 0x4000>;
                        phandle = <0x68>;
                };

                blp_cips_pspmc_0_psv_xram_xmpu_bank_4: blp_cips_pspmc_0_psv_xram_xmpu_bank_4@ff93c000 {
                        compatible = "xlnx,psv-xram-xmpu-bank-1.0";
                        status = "okay";
                        xlnx,ip-name = "psv_xram_xmpu_bank";
                        reg = <0x0 0xff93c000 0x0 0x4000>;
                        phandle = <0x69>;
                };

                gic: interrupt-controller@f9000000 {
                        phandle = <0x45>;
                        xlnx,ip-name = "psv_acpu_gic";
                        xlnx,apu-gic-its-ctl = <0xf9020000>;
                        status = "okay";
                        interrupts = <0x1 0x9 0x4>;
                        interrupt-parent = <&gic>;
                        interrupt-controller;
                        reg = <0x0 0xf9000000 0x0 0x80000 0x0 0xf9080000 0x0 0x80000>;
                        ranges;
                        #size-cells = <0x2>;
                        #address-cells = <0x2>;
                        #interrupt-cells = <0x3>;
                        compatible = "arm,gic-v3";

                        gic_its: msi-controller@f9020000 {
                                phandle = <0x4>;
                                reg = <0x0 0xf9020000 0x0 0x20000>;
                                #msi-cells = <0x1>;
                                msi-controller;
                                status = "okay";
                                compatible = "arm,gic-v3-its";
                        };
                };
        };

        amba_xppu: indirect-bus@1 {
                compatible = "indirect-bus";
                #address-cells = <0x2>;
                #size-cells = <0x2>;
                phandle = <0x15a>;

                lpd_xppu: xppu@ff990000 {
                        compatible = "xlnx,xppu";
                        #firewall-cells = <0x0>;
                        reg = <0x0 0xff990000 0x0 0x2000>;
                        status = "okay";
                        xlnx,ip-name = "psv_lpd_xppu";
                        phandle = <0x6f>;
                };

                pmc_xppu: xppu@f1310000 {
                        compatible = "xlnx,xppu";
                        #firewall-cells = <0x0>;
                        reg = <0x0 0xf1310000 0x0 0x2000>;
                        status = "okay";
                        xlnx,ip-name = "psv_pmc_xppu";
                        phandle = <0x42>;
                };

                pmc_xppu_npi: xppu@f1300000 {
                        compatible = "xlnx,xppu";
                        #firewall-cells = <0x0>;
                        reg = <0x0 0xf1300000 0x0 0x2000>;
                        status = "okay";
                        xlnx,ip-name = "psv_pmc_xppu_npi";
                        phandle = <0x41>;
                };
        };

        amba_xmpu: indirect-bus@2 {
                compatible = "indirect-bus";
                #address-cells = <0x2>;
                #size-cells = <0x2>;
                phandle = <0x15b>;

                fpd_xmpu: xmpu@fd390000 {
                        compatible = "xlnx,xmpu";
                        #firewall-cells = <0x0>;
                        reg = <0x0 0xfd390000 0x0 0x1000>;
                        status = "okay";
                        xlnx,ip-name = "psv_fpd_slave_xmpu";
                        phandle = <0x4b>;
                };

                pmc_xmpu: xmpu@f12f0000 {
                        compatible = "xlnx,xmpu";
                        #firewall-cells = <0x0>;
                        reg = <0x0 0xf12f0000 0x0 0x1000>;
                        status = "okay";
                        xlnx,ip-name = "psv_pmc_xmpu";
                        phandle = <0x40>;
                };

                ocm_xmpu: xmpu@ff980000 {
                        compatible = "xlnx,xmpu";
                        #firewall-cells = <0x0>;
                        reg = <0x0 0xff980000 0x0 0x1000>;
                        status = "okay";
                        xlnx,ip-name = "psv_ocm_xmpu";
                        phandle = <0x6e>;
                };

                ddrmc_xmpu_1: xmpu@f6220000 {
                        compatible = "xlnx,xmpu";
                        #firewall-cells = <0x0>;
                        reg = <0x0 0xf6220000 0x0 0x1000>;
                        status = "disabled";
                        phandle = <0x15d>;
                };

                ddrmc_xmpu_2: xmpu@f6390000 {
                        compatible = "xlnx,xmpu";
                        #firewall-cells = <0x0>;
                        reg = <0x0 0xf6390000 0x0 0x1000>;
                        status = "disabled";
                        phandle = <0x15e>;
                };

                ddrmc_xmpu_3: xmpu@f6500000 {
                        compatible = "xlnx,xmpu";
                        #firewall-cells = <0x0>;
                        reg = <0x0 0xf6500000 0x0 0x1000>;
                        status = "disabled";
                        phandle = <0x15f>;
                };
        };

        pl_alt_ref_clk: pl_alt_ref_clk {
                bootph-all;
                compatible = "fixed-clock";
                #clock-cells = <0x0>;
                clock-frequency = <0x1fca055>;
                phandle = <0xac>;
        };

        ref_clk: ref_clk {
                bootph-all;
                compatible = "fixed-clock";
                #clock-cells = <0x0>;
                clock-frequency = <0x1fca034>;
                phandle = <0xab>;
        };

        can0_clk: can0_clk {
                #clock-cells = <0x0>;
                compatible = "fixed-factor-clock";
                clocks = <&versal_clk 0x60>;
                clock-div = <0x2>;
                clock-mult = <0x1>;
                phandle = <0xa6>;
        };

        can1_clk: can1_clk {
                #clock-cells = <0x0>;
                compatible = "fixed-factor-clock";
                clocks = <&versal_clk 0x61>;
                clock-div = <0x2>;
                clock-mult = <0x1>;
                phandle = <0xa7>;
        };

        firmware {

                versal_firmware: versal-firmware {
                        compatible = "xlnx,versal-firmware";
                        interrupt-parent = <&gic>;
                        bootph-all;
                        method = "smc";
                        #power-domain-cells = <0x1>;
                        phandle = <0x85>;

                        versal_clk: clock-controller {
                                bootph-all;
                                #clock-cells = <0x1>;
                                compatible = "xlnx,versal-clk";
                                clocks = <&ref_clk>,
                                 <&pl_alt_ref_clk>;
                                clock-names = "ref_clk", "pl_alt_ref_clk";
                                phandle = <0x86>;
                        };

                        zynqmp_power: zynqmp-power {
                                compatible = "xlnx,zynqmp-power";
                                phandle = <0x160>;
                        };

                        versal_reset: reset-controller {
                                compatible = "xlnx,versal-reset";
                                #reset-cells = <0x1>;
                                phandle = <0xa8>;
                        };

                        pinctrl0: pinctrl {
                                compatible = "xlnx,versal-pinctrl";
                                phandle = <0x161>;
                        };

                        versal_sec_cfg: versal-sec-cfg {
                                compatible = "xlnx,versal-sec-cfg";
                                #address-cells = <0x1>;
                                #size-cells = <0x1>;
                                phandle = <0x162>;

                                bbram_zeroize: bbram-zeroize@4 {
                                        reg = <0x4 0x4>;
                                        phandle = <0x163>;
                                };

                                bbram_key: bbram-key@10 {
                                        reg = <0x10 0x20>;
                                        phandle = <0x164>;
                                };

                                bbram_usr: bbram-usr@30 {
                                        reg = <0x30 0x4>;
                                        phandle = <0x165>;
                                };

                                bbram_lock: bbram-lock@48 {
                                        reg = <0x48 0x4>;
                                        phandle = <0x166>;
                                };

                                user_key0: user-key@110 {
                                        reg = <0x110 0x20>;
                                        phandle = <0x167>;
                                };

                                user_key1: user-key@130 {
                                        reg = <0x130 0x20>;
                                        phandle = <0x168>;
                                };

                                user_key2: user-key@150 {
                                        reg = <0x150 0x20>;
                                        phandle = <0x169>;
                                };

                                user_key3: user-key@170 {
                                        reg = <0x170 0x20>;
                                        phandle = <0x16a>;
                                };

                                user_key4: user-key@190 {
                                        reg = <0x190 0x20>;
                                        phandle = <0x16b>;
                                };

                                user_key5: user-key@1b0 {
                                        reg = <0x1b0 0x20>;
                                        phandle = <0x16c>;
                                };

                                user_key6: user-key@1d0 {
                                        reg = <0x1d0 0x20>;
                                        phandle = <0x16d>;
                                };

                                user_key7: user-key@1f0 {
                                        reg = <0x1f0 0x20>;
                                        phandle = <0x16e>;
                                };
                        };
                };
        };

        amba_pl: amba_pl {
                ranges;
                compatible = "simple-bus";
                #address-cells = <0x2>;
                #size-cells = <0x2>;
                firmware-name = "ve2302_pcie_qdma_base.pdi";
                phandle = <0x16f>;

                fpga_PR: fpga-PR {
                        ranges;
                        compatible = "fpga-region";
                        #address-cells = <0x2>;
                        #size-cells = <0x2>;
                        phandle = <0x170>;
                };

                misc_clk_0: misc_clk_0 {
                        compatible = "fixed-clock";
                        clock-frequency = <0x7735940>;
                        #clock-cells = <0x0>;
                        phandle = <0xad>;
                };

                blp_blp_logic_ert_support_axi_intc_0_31: interrupt-controller@20202020000 {
                        #interrupt-cells = <0x2>;
                        interrupts = <0x0 0x5d 0x1>;
                        xlnx,sense-of-irq-edge-type = "Rising";
                        xlnx,edk-special = "INTR_CTRL";
                        xlnx,kind-of-intr = <0x1>;
                        xlnx,kind-of-edge = <0xffffffff>;
                        xlnx,irq-is-level = <0x0>;
                        xlnx,has-ivr = <0x1>;
                        compatible = "xlnx,axi-intc-4.1", "xlnx,xps-intc-1.00.a";
                        xlnx,disable-synchronizers = <0x0>;
                        xlnx,kind-of-lvl = <0xffffffff>;
                        xlnx,ivar-reset-value = <0x10>;
                        xlnx,irq-active = <0x1>;
                        interrupt-parent = <&gic>;
                        xlnx,en-cascade-mode = <0x0>;
                        xlnx,ip-name = "axi_intc";
                        xlnx,has-ilr = <0x0>;
                        reg = <0x202 0x2020000 0x0 0x1000>;
                        xlnx,addr-width = <0x20>;
                        clocks = <&versal_clk 0x41>;
                        xlnx,s-axi-aclk-freq-mhz = <0x5f5e0a4>;
                        xlnx,num-sw-intr = <0x0>;
                        xlnx,irq-connection = <0x1>;
                        xlnx,num-intr-inputs = <0x20>;
                        xlnx,has-sie = <0x1>;
                        xlnx,enable-async = <0x0>;
                        xlnx,has-cie = <0x1>;
                        xlnx,num-sync-ff = <0x2>;
                        xlnx,edk-iptype = "PERIPHERAL";
                        xlnx,mb-clk-not-connected = <0x1>;
                        xlnx,has-ipr = <0x1>;
                        xlnx,sense-of-irq-level-type = "Active_High";
                        xlnx,cascade-master = <0x0>;
                        xlnx,processor-clk-freq-mhz = <0x64>;
                        status = "okay";
                        xlnx,is-fast = <0x0>;
                        clock-names = "s_axi_aclk";
                        xlnx,has-fast = <0x0>;
                        xlnx,ivar-rst-val = <0x10>;
                        interrupt-controller;
                        interrupt-names = "irq";
                        xlnx,async-intr = <0xffffffff>;
                        phandle = <0x82>;
                };

                blp_blp_logic_axi_firewall_user: axi_firewall@80001000 {
                        xlnx,protocol = <0x2>;
                        compatible = "xlnx,axi-firewall-1.2";
                        xlnx,enable-pipelining = <0x1>;
                        xlnx,enable-protocol-checks = <0x1>;
                        xlnx,awuser-width = <0x0>;
                        xlnx,has-rresp = <0x1>;
                        xlnx,has-bresp = <0x1>;
                        xlnx,supports-narrow = <0x0>;
                        xlnx,read-write-mode = "READ_WRITE";
                        xlnx,has-prot = <0x1>;
                        xlnx,wdata-width = <0x20>;
                        xlnx,ruser-width = <0x0>;
                        xlnx,buser-width = <0x0>;
                        xlnx,has-aclken = <0x0>;
                        xlnx,ip-name = "axi_firewall";
                        xlnx,num-write-threads = <0x1>;
                        reg = <0x0 0x80001000 0x0 0x1000>;
                        xlnx,addr-width = <0x40>;
                        clocks = <&versal_clk 0x41>;
                        xlnx,num-read-threads = <0x1>;
                        xlnx,has-lock = <0x1>;
                        xlnx,id-width = <0x0>;
                        xlnx,enable-initial-delay = <0x1>;
                        xlnx,has-wstrb = <0x1>;
                        xlnx,has-aresetn = <0x1>;
                        xlnx,wuser-width = <0x0>;
                        xlnx,has-qos = <0x1>;
                        xlnx,edk-iptype = "PERIPHERAL";
                        xlnx,has-region = <0x1>;
                        xlnx,has-cache = <0x1>;
                        xlnx,num-write-outstanding = <0x20>;
                        xlnx,enable-prescaler = <0x1>;
                        xlnx,num-read-outstanding = <0x20>;
                        status = "okay";
                        clock-names = "aclk";
                        xlnx,data-width = <0x20>;
                        xlnx,aruser-width = <0x0>;
                        xlnx,firewall-mode = <0x0>;
                        xlnx,enable-ctl-clock = <0x0>;
                        xlnx,has-burst = <0x1>;
                        xlnx,rdata-width = <0x20>;
                        xlnx,mask-err-resp = <0x1>;
                        xlnx,enable-timeout-checks = <0x1>;
                        phandle = <0x9>;
                };

                blp_blp_logic_axi_intc_gcq_apu: interrupt-controller@402031000 {
                        #interrupt-cells = <0x2>;
                        interrupts = <0x0 0x5f 0x1>;
                        xlnx,sense-of-irq-edge-type = "Rising";
                        xlnx,edk-special = "INTR_CTRL";
                        xlnx,kind-of-intr = <0x1>;
                        xlnx,kind-of-edge = <0xffffffff>;
                        xlnx,irq-is-level = <0x0>;
                        xlnx,has-ivr = <0x1>;
                        compatible = "xlnx,axi-intc-4.1", "xlnx,xps-intc-1.00.a";
                        xlnx,disable-synchronizers = <0x0>;
                        xlnx,kind-of-lvl = <0xffffffff>;
                        xlnx,ivar-reset-value = <0x10>;
                        xlnx,irq-active = <0x1>;
                        interrupt-parent = <&gic>;
                        xlnx,en-cascade-mode = <0x0>;
                        xlnx,ip-name = "axi_intc";
                        xlnx,has-ilr = <0x0>;
                        reg = <0x4 0x2031000 0x0 0x1000>;
                        xlnx,addr-width = <0x20>;
                        clocks = <&versal_clk 0x41>;
                        xlnx,s-axi-aclk-freq-mhz = <0x5f5e0a4>;
                        xlnx,num-sw-intr = <0x0>;
                        xlnx,irq-connection = <0x1>;
                        xlnx,num-intr-inputs = <0x1>;
                        xlnx,has-sie = <0x1>;
                        xlnx,enable-async = <0x0>;
                        xlnx,has-cie = <0x1>;
                        xlnx,num-sync-ff = <0x2>;
                        xlnx,edk-iptype = "PERIPHERAL";
                        xlnx,mb-clk-not-connected = <0x1>;
                        xlnx,has-ipr = <0x1>;
                        xlnx,sense-of-irq-level-type = "Active_High";
                        xlnx,cascade-master = <0x0>;
                        xlnx,processor-clk-freq-mhz = <0x64>;
                        status = "okay";
                        xlnx,is-fast = <0x0>;
                        clock-names = "s_axi_aclk";
                        xlnx,has-fast = <0x0>;
                        xlnx,ivar-rst-val = <0x10>;
                        interrupt-controller;
                        interrupt-names = "irq";
                        xlnx,async-intr = <0xfffffffe>;
                        phandle = <0x81>;
                };

                blp_blp_logic_axi_intc_uart_apu: interrupt-controller@402030000 {
                        #interrupt-cells = <0x2>;
                        interrupts = <0x0 0x5e 0x1>;
                        xlnx,sense-of-irq-edge-type = "Rising";
                        xlnx,edk-special = "INTR_CTRL";
                        xlnx,kind-of-intr = <0x1>;
                        xlnx,kind-of-edge = <0xffffffff>;
                        xlnx,irq-is-level = <0x0>;
                        xlnx,has-ivr = <0x1>;
                        compatible = "xlnx,axi-intc-4.1", "xlnx,xps-intc-1.00.a";
                        xlnx,disable-synchronizers = <0x0>;
                        xlnx,kind-of-lvl = <0xffffffff>;
                        xlnx,ivar-reset-value = <0x10>;
                        xlnx,irq-active = <0x1>;
                        interrupt-parent = <&gic>;
                        xlnx,en-cascade-mode = <0x0>;
                        xlnx,ip-name = "axi_intc";
                        xlnx,has-ilr = <0x0>;
                        reg = <0x4 0x2030000 0x0 0x1000>;
                        xlnx,addr-width = <0x20>;
                        clocks = <&versal_clk 0x41>;
                        xlnx,s-axi-aclk-freq-mhz = <0x5f5e0a4>;
                        xlnx,num-sw-intr = <0x0>;
                        xlnx,irq-connection = <0x1>;
                        xlnx,num-intr-inputs = <0x2>;
                        xlnx,has-sie = <0x1>;
                        xlnx,enable-async = <0x0>;
                        xlnx,has-cie = <0x1>;
                        xlnx,num-sync-ff = <0x2>;
                        xlnx,edk-iptype = "PERIPHERAL";
                        xlnx,mb-clk-not-connected = <0x1>;
                        xlnx,has-ipr = <0x1>;
                        xlnx,sense-of-irq-level-type = "Active_High";
                        xlnx,cascade-master = <0x0>;
                        xlnx,processor-clk-freq-mhz = <0x64>;
                        status = "okay";
                        xlnx,is-fast = <0x0>;
                        clock-names = "s_axi_aclk";
                        xlnx,has-fast = <0x0>;
                        xlnx,ivar-rst-val = <0x10>;
                        interrupt-controller;
                        interrupt-names = "irq";
                        xlnx,async-intr = <0xfffffffe>;
                        phandle = <0x80>;
                };

                blp_blp_logic_axi_uart_apu0: serial@402020000 {
                        interrupts = <0x0 0x0>;
                        compatible = "xlnx,axi-uartlite-2.0", "xlnx,xps-uartlite-1.00.a";
                        xlnx,uartlite-board-interface = "Custom";
                        xlnx,s-axi-aclk-freq-hz-d = <0x5f5e0a4>;
                        interrupt-parent = <&blp_blp_logic_axi_intc_uart_apu>;
                        xlnx,ip-name = "axi_uartlite";
                        reg = <0x4 0x2020000 0x0 0x1000>;
                        xlnx,baudrate = <0x38400>;
                        clocks = <&versal_clk 0x41>;
                        current-speed = <0x38400>;
                        xlnx,use-parity = <0x0>;
                        xlnx,edk-iptype = "PERIPHERAL";
                        xlnx,odd-parity = <0x0>;
                        status = "okay";
                        clock-names = "s_axi_aclk";
                        interrupt-names = "interrupt";
                        xlnx,data-bits = <0x8>;
                        xlnx,parity = "No_Parity";
                        phandle = <0x7f>;
                };

                blp_blp_logic_axi_uart_rpu: serial@80021000 {
                        interrupts = <0x0 0x57 0x1>;
                        compatible = "xlnx,axi-uartlite-2.0", "xlnx,xps-uartlite-1.00.a";
                        xlnx,uartlite-board-interface = "Custom";
                        xlnx,s-axi-aclk-freq-hz-d = <0x5f5e0a4>;
                        interrupt-parent = <&gic>;
                        xlnx,ip-name = "axi_uartlite";
                        reg = <0x0 0x80021000 0x0 0x1000>;
                        xlnx,baudrate = <0x38400>;
                        clocks = <&versal_clk 0x41>;
                        current-speed = <0x38400>;
                        xlnx,use-parity = <0x0>;
                        xlnx,edk-iptype = "PERIPHERAL";
                        xlnx,odd-parity = <0x0>;
                        status = "okay";
                        clock-names = "s_axi_aclk";
                        interrupt-names = "interrupt";
                        xlnx,data-bits = <0x8>;
                        xlnx,parity = "No_Parity";
                        phandle = <0xd>;
                };

                blp_blp_logic_base_clocking_pr_reset_gpio: gpio@80020000 {
                        xlnx,gpio-board-interface = "Custom";
                        compatible = "xlnx,axi-gpio-2.0", "xlnx,xps-gpio-1.00.a";
                        xlnx,all-outputs = <0x1>;
                        #gpio-cells = <0x2>;
                        xlnx,gpio-width = <0x2>;
                        xlnx,dout-default = <0x0>;
                        xlnx,is-dual = <0x1>;
                        xlnx,ip-name = "axi_gpio";
                        xlnx,tri-default-2 = <0xffffffff>;
                        reg = <0x0 0x80020000 0x0 0x1000>;
                        xlnx,all-inputs-2 = <0x1>;
                        clocks = <&versal_clk 0x41>;
                        xlnx,all-outputs-2 = <0x0>;
                        gpio-controller;
                        xlnx,interrupt-present = <0x0>;
                        xlnx,gpio2-board-interface = "Custom";
                        xlnx,edk-iptype = "PERIPHERAL";
                        xlnx,dout-default-2 = <0x0>;
                        status = "okay";
                        xlnx,gpio2-width = <0x2>;
                        clock-names = "s_axi_aclk";
                        xlnx,tri-default = <0xffffffff>;
                        xlnx,all-inputs = <0x0>;
                        phandle = <0xc>;
                };

                blp_blp_logic_gcq_m2r: cmd_queue@20102010000 {
                        compatible = "xlnx,cmd-queue-2.0";
                        interrupts = <0x0 0x54 0x1>;
                        interrupt-parent = <&gic>;
                        xlnx,ip-name = "cmd_queue";
                        reg = <0x0 0x80010000 0x0 0x1000 0x201 0x2010000 0x0 0x1000>;
                        clocks = <&versal_clk 0x41>;
                        xlnx,s01-addr-width = <0xc>;
                        xlnx,edk-iptype = "PERIPHERAL";
                        status = "okay";
                        clock-names = "aclk";
                        xlnx,s00-addr-width = <0xc>;
                        interrupt-names = "irq_sq";
                        phandle = <0xa>;
                };

                blp_blp_logic_gcq_r2a: cmd_queue@80011000 {
                        compatible = "xlnx,cmd-queue-2.0";
                        interrupts = <0x0 0x55 0x1 0x0 0x5c 0x1>;
                        interrupt-parent = <&gic>;
                        xlnx,ip-name = "cmd_queue";
                        reg = <0x0 0x80011000 0x0 0x1000 0x4 0x2000000 0x0 0x1000>;
                        clocks = <&versal_clk 0x41>;
                        xlnx,s01-addr-width = <0xc>;
                        xlnx,edk-iptype = "PERIPHERAL";
                        status = "okay";
                        clock-names = "aclk";
                        xlnx,s00-addr-width = <0xc>;
                        interrupt-names = "irq_cq", "irq_sq";
                        phandle = <0xb>;
                };

                blp_blp_logic_gcq_u2a_0: cmd_queue@20202010000 {
                        compatible = "xlnx,cmd-queue-2.0";
                        interrupts = <0x0 0x0>;
                        interrupt-parent = <&blp_blp_logic_axi_intc_gcq_apu>;
                        xlnx,ip-name = "cmd_queue";
                        reg = <0x4 0x2010000 0x0 0x1000 0x202 0x2010000 0x0 0x1000>;
                        clocks = <&versal_clk 0x41>;
                        xlnx,s01-addr-width = <0xc>;
                        xlnx,edk-iptype = "PERIPHERAL";
                        status = "okay";
                        clock-names = "aclk";
                        xlnx,s00-addr-width = <0xc>;
                        interrupt-names = "irq_sq";
                        phandle = <0x7e>;
                };

                blp_blp_logic_pfm_irq_ctlr: pfm_irq_ctlr@80044000 {
                        compatible = "xlnx,pfm-irq-ctlr-1.0";
                        xlnx,num-of-irq-pf0 = <0x1>;
                        xlnx,num-of-irq-pf1 = <0x1>;
                        xlnx,ip-name = "pfm_irq_ctlr";
                        xlnx,cpm-type = <0x0>;
                        xlnx,num-of-pfs = <0x2>;
                        xlnx,num-of-irq-pf2 = <0x20>;
                        reg = <0x0 0x80044000 0x0 0x1000>;
                        xlnx,addr-width = <0xa>;
                        clocks = <&misc_clk_0>;
                        xlnx,num-of-irq-pf3 = <0x20>;
                        xlnx,edk-iptype = "PERIPHERAL";
                        xlnx,axi-ctrl-en = <0x1>;
                        xlnx,edge-select-pf0 = <0x0>;
                        status = "okay";
                        xlnx,edge-select-pf1 = <0x0>;
                        clock-names = "aclk";
                        xlnx,edge-select-pf2 = <0x0>;
                        xlnx,max-pf-length = <0x20>;
                        xlnx,edge-select-pf3 = <0x0>;
                        phandle = <0x11>;
                };

                blp_blp_logic_ulp_clocking_clkwiz_aclk_kernel_00: clk_wizard@80042000 {
                        reg = <0x0 0x80042000 0x0 0x1000>;
                        clock-names = "clk_in1", "s_axi_aclk";
                        xlnx,nr-outputs = <0x1>;
                        compatible = "xlnx,clk-wizard-1.0", "xlnx,versal-clk-wizard";
                        xlnx,speed-grade = <0x2>;
                        clocks = <&versal_clk 0x42>,
                         <&versal_clk 0x42>;
                        #clock-cells = <0x1>;
                        phandle = <0xf>;
                };

                blp_blp_logic_ulp_clocking_clkwiz_aclk_kernel_01: clk_wizard@80043000 {
                        reg = <0x0 0x80043000 0x0 0x1000>;
                        clock-names = "clk_in1", "s_axi_aclk";
                        xlnx,nr-outputs = <0x1>;
                        compatible = "xlnx,clk-wizard-1.0", "xlnx,versal-clk-wizard";
                        xlnx,speed-grade = <0x2>;
                        clocks = <&versal_clk 0x42>,
                         <&versal_clk 0x42>;
                        #clock-cells = <0x1>;
                        phandle = <0x10>;
                };

                blp_blp_logic_ulp_clocking_shell_utils_ucc: shell_utils_ucc@80030000 {
                        compatible = "xlnx,shell-utils-ucc-1.0";
                        xlnx,ext-tog-enable = <0x1>;
                        xlnx,num-clocks = <0x2>;
                        xlnx,ip-name = "shell_utils_ucc";
                        reg = <0x0 0x80030000 0x0 0x10000>;
                        xlnx,freq-cnt-ref-clk-hz = <0x8235>;
                        clocks = <&versal_clk 0x41>,
                         <&versal_clk 0x42>,
                         <&misc_clk_0>,
                         <&blp_blp_logic_ulp_clocking_clkwiz_aclk_kernel_00 0x0>,
                         <&blp_blp_logic_ulp_clocking_clkwiz_aclk_kernel_01 0x0>;
                        xlnx,edk-iptype = "PERIPHERAL";
                        status = "okay";
                        clock-names = "aclk_ctrl", "aclk_freerun", "aclk_pcie", "clk_in_kernel_00", "clk_in_kernel_01";
                        phandle = <0xe>;
                };

                blp_blp_logic_uuid_register: uuid_register@20102002000 {
                        compatible = "xlnx,uuid-register-1.0";
                        status = "okay";
                        clock-names = "S_AXI_ACLK";
                        xlnx,ip-name = "uuid_register";
                        xlnx,edk-iptype = "PERIPHERAL";
                        reg = <0x0 0x80045000 0x0 0x1000 0x201 0x2002000 0x0 0x1000>;
                        clocks = <&versal_clk 0x41>;
                        phandle = <0x12>;
                };
        };

        blp_axi_noc_mc_1x_ddr_memory: memory@00000000 {
                compatible = "xlnx,axi-noc-1.1";
                xlnx,ip-name = "axi_noc";
                device_type = "memory";
                reg = <0x0 0x0 0x0 0x80000000 0x500 0x0 0x1 0x80000000>;
                memory_type = "memory";
                phandle = <0x3>;
        };

        chosen {
                stdout-path = "serial0:115200";
                bootargs = "earlycon clk_ignore_unused";
        };

        aliases {
                serial4 = "/amba_pl/serial@20102020000";
                serial0 = "/axi/serial@ff000000";
                serial5 = "/amba_pl/serial@80021000";
                serial1 = "/axi/serial@ff010000";
                serial6 = "/axi/coresight@f0800000";
                serial2 = "/amba_pl/serial@402020000";
                serial3 = "/amba_pl/serial@20102021000";
                i2c0 = "/axi/i2c@ff020000";
        };

        onewire {
                compatible = "w1-gpio";
                gpios = <0x58 0x4 0x0>;
        };

        __symbols__ {
                cpus_a72 = "/cpus-a72@0";
                psv_cortexa72_0 = "/cpus-a72@0/cpu@0";
                psv_cortexa72_1 = "/cpus-a72@0/cpu@1";
                CPU_SLEEP_0 = "/cpus-a72@0/idle-states/cpu-sleep-0";
                cpu_opp_table = "/opp-table-cpu";
                dcc = "/dcc";
                fpga = "/fpga-region";
                psci = "/psci";
                timer = "/timer";
                versal_fpga = "/versal-fpga";
                sensor0 = "/versal-thermal-sensor";
                versal_thermal = "/thermal-zones/versal-thermal";
                temp_alert = "/thermal-zones/versal-thermal/trips/temp-alert";
                ot_crit = "/thermal-zones/versal-thermal/trips/ot-crit";
                amba_apu = "/apu-bus";
                gic_its = "/axi/interrupt-controller@f9000000/msi-controller@f9020000";
                amba = "/axi";
                imux = "/axi/interrupt-multiplex";
                can0 = "/axi/can@ff060000";
                can1 = "/axi/can@ff070000";
                cci = "/axi/cci@fd000000";
                cci_pmu = "/axi/cci@fd000000/pmu@10000";
                lpd_dma_chan0 = "/axi/dma-controller@ffa80000";
                lpd_dma_chan1 = "/axi/dma-controller@ffa90000";
                lpd_dma_chan2 = "/axi/dma-controller@ffaa0000";
                lpd_dma_chan3 = "/axi/dma-controller@ffab0000";
                lpd_dma_chan4 = "/axi/dma-controller@ffac0000";
                lpd_dma_chan5 = "/axi/dma-controller@ffad0000";
                lpd_dma_chan6 = "/axi/dma-controller@ffae0000";
                lpd_dma_chan7 = "/axi/dma-controller@ffaf0000";
                gem0 = "/axi/ethernet@ff0c0000";
                gem1 = "/axi/ethernet@ff0d0000";
                gpio0 = "/axi/gpio@ff0b0000";
                gpio1 = "/axi/gpio@f1020000";
                i2c0 = "/axi/i2c@ff020000";
                i2c1 = "/axi/i2c@ff030000";
                i2c2 = "/axi/i2c@f1000000";
                mc1 = "/axi/memory-controller@f62c0000";
                mc2 = "/axi/memory-controller@f6430000";
                mc3 = "/axi/memory-controller@f65a0000";
                ocm = "/axi/memory-controller@ff960000";
                rtc = "/axi/rtc@f12a0000";
                sdhci0 = "/axi/mmc@f1040000";
                sdhci1 = "/axi/mmc@f1050000";
                serial0 = "/axi/serial@ff000000";
                serial1 = "/axi/serial@ff010000";
                smmu = "/axi/iommu@fd800000";
                ospi = "/axi/spi@f1010000";
                qspi = "/axi/spi@f1030000";
                spi0 = "/axi/spi@ff040000";
                spi1 = "/axi/spi@ff050000";
                sysmon0 = "/axi/sysmon@f1270000";
                sysmon1 = "/axi/sysmon@109270000";
                sysmon2 = "/axi/sysmon@111270000";
                sysmon3 = "/axi/sysmon@119270000";
                ttc0 = "/axi/timer@ff0e0000";
                ttc1 = "/axi/timer@ff0f0000";
                ttc2 = "/axi/timer@ff100000";
                ttc3 = "/axi/timer@ff110000";
                usb0 = "/axi/usb@ff9d0000";
                dwc3_0 = "/axi/usb@ff9d0000/usb@fe200000";
                cpm_pciea = "/axi/pci@fca10000";
                pcie_intc_0 = "/axi/pci@fca10000/interrupt-controller";
                cpm5_pcie = "/axi/pcie@fcdd0000";
                pcie_intc_2 = "/axi/pcie@fcdd0000/interrupt-controller";
                watchdog = "/axi/watchdog@fd4d0000";
                watchdog1 = "/axi/watchdog@ff120000";
                xilsem_edac = "/axi/edac@f2014050";
                dma0 = "/axi/pmcdma@f11c0000";
                dma1 = "/axi/pmcdma@f11d0000";
                coresight = "/axi/coresight@f0800000";
                blp_cips_pspmc_0_psv_cpm = "/axi/blp_cips_pspmc_0_psv_cpm@0";
                blp_cips_pspmc_0_psv_xram_atm = "/axi/blp_cips_pspmc_0_psv_xram_atm@ff970000";
                blp_cips_pspmc_0_psv_xram_ctrl_1 = "/axi/blp_cips_pspmc_0_psv_xram_ctrl_1@ff8e0000";
                blp_cips_pspmc_0_psv_xram_ctrl_2 = "/axi/blp_cips_pspmc_0_psv_xram_ctrl_2@ff8f0000";
                blp_cips_pspmc_0_psv_xram_ctrl_3 = "/axi/blp_cips_pspmc_0_psv_xram_ctrl_3@ff900000";
                blp_cips_pspmc_0_psv_xram_ctrl_4 = "/axi/blp_cips_pspmc_0_psv_xram_ctrl_4@ff910000";
                blp_cips_pspmc_0_psv_xram_global_ctrl = "/axi/blp_cips_pspmc_0_psv_xram_global_ctrl@ff950000";
                blp_cips_pspmc_0_psv_xram_gpv = "/axi/blp_cips_pspmc_0_psv_xram_gpv@ff940000";
                blp_cips_pspmc_0_psv_xram_xmpu_bank_1 = "/axi/blp_cips_pspmc_0_psv_xram_xmpu_bank_1@ff930000";
                blp_cips_pspmc_0_psv_xram_xmpu_bank_2 = "/axi/blp_cips_pspmc_0_psv_xram_xmpu_bank_2@ff934000";
                blp_cips_pspmc_0_psv_xram_xmpu_bank_3 = "/axi/blp_cips_pspmc_0_psv_xram_xmpu_bank_3@ff938000";
                blp_cips_pspmc_0_psv_xram_xmpu_bank_4 = "/axi/blp_cips_pspmc_0_psv_xram_xmpu_bank_4@ff93c000";
                amba_xppu = "/indirect-bus@1";
                lpd_xppu = "/indirect-bus@1/xppu@ff990000";
                pmc_xppu = "/indirect-bus@1/xppu@f1310000";
                pmc_xppu_npi = "/indirect-bus@1/xppu@f1300000";
                amba_xmpu = "/indirect-bus@2";
                fpd_xmpu = "/indirect-bus@2/xmpu@fd390000";
                pmc_xmpu = "/indirect-bus@2/xmpu@f12f0000";
                ocm_xmpu = "/indirect-bus@2/xmpu@ff980000";
                ddrmc_xmpu_1 = "/indirect-bus@2/xmpu@f6220000";
                ddrmc_xmpu_2 = "/indirect-bus@2/xmpu@f6390000";
                ddrmc_xmpu_3 = "/indirect-bus@2/xmpu@f6500000";
                pl_alt_ref_clk = "/pl_alt_ref_clk";
                ref_clk = "/ref_clk";
                can0_clk = "/can0_clk";
                can1_clk = "/can1_clk";
                versal_firmware = "/firmware/versal-firmware";
                versal_clk = "/firmware/versal-firmware/clock-controller";
                zynqmp_power = "/firmware/versal-firmware/zynqmp-power";
                versal_reset = "/firmware/versal-firmware/reset-controller";
                pinctrl0 = "/firmware/versal-firmware/pinctrl";
                versal_sec_cfg = "/firmware/versal-firmware/versal-sec-cfg";
                bbram_zeroize = "/firmware/versal-firmware/versal-sec-cfg/bbram-zeroize@4";
                bbram_key = "/firmware/versal-firmware/versal-sec-cfg/bbram-key@10";
                bbram_usr = "/firmware/versal-firmware/versal-sec-cfg/bbram-usr@30";
                bbram_lock = "/firmware/versal-firmware/versal-sec-cfg/bbram-lock@48";
                user_key0 = "/firmware/versal-firmware/versal-sec-cfg/user-key@110";
                user_key1 = "/firmware/versal-firmware/versal-sec-cfg/user-key@130";
                user_key2 = "/firmware/versal-firmware/versal-sec-cfg/user-key@150";
                user_key3 = "/firmware/versal-firmware/versal-sec-cfg/user-key@170";
                user_key4 = "/firmware/versal-firmware/versal-sec-cfg/user-key@190";
                user_key5 = "/firmware/versal-firmware/versal-sec-cfg/user-key@1b0";
                user_key6 = "/firmware/versal-firmware/versal-sec-cfg/user-key@1d0";
                user_key7 = "/firmware/versal-firmware/versal-sec-cfg/user-key@1f0";
                amba_pl = "/amba_pl";
                fpga_PR = "/amba_pl/fpga-PR";
                misc_clk_0 = "/amba_pl/misc_clk_0";
                blp_blp_logic_ert_support_axi_intc_0_31 = "/amba_pl/interrupt-controller@20202020000";
                blp_blp_logic_axi_firewall_user = "/amba_pl/axi_firewall@80001000";
                blp_blp_logic_axi_intc_gcq_apu = "/amba_pl/interrupt-controller@402031000";
                blp_blp_logic_axi_intc_uart_apu = "/amba_pl/interrupt-controller@402030000";
                blp_blp_logic_axi_uart_apu0 = "/amba_pl/serial@402020000";
                blp_blp_logic_axi_uart_rpu = "/amba_pl/serial@80021000";
                blp_blp_logic_base_clocking_pr_reset_gpio = "/amba_pl/gpio@80020000";
                blp_blp_logic_gcq_m2r = "/amba_pl/cmd_queue@20102010000";
                blp_blp_logic_gcq_r2a = "/amba_pl/cmd_queue@80011000";
                blp_blp_logic_gcq_u2a_0 = "/amba_pl/cmd_queue@20202010000";
                blp_blp_logic_pfm_irq_ctlr = "/amba_pl/pfm_irq_ctlr@80044000";
                blp_blp_logic_ulp_clocking_clkwiz_aclk_kernel_00 = "/amba_pl/clk_wizard@80042000";
                blp_blp_logic_ulp_clocking_clkwiz_aclk_kernel_01 = "/amba_pl/clk_wizard@80043000";
                blp_blp_logic_ulp_clocking_shell_utils_ucc = "/amba_pl/shell_utils_ucc@80030000";
                blp_blp_logic_uuid_register = "/amba_pl/uuid_register@20102002000";
                blp_axi_noc_mc_1x_ddr_memory = "/memory@00000000";
                gic = "/axi/interrupt-controller@f9000000";
        };
};
